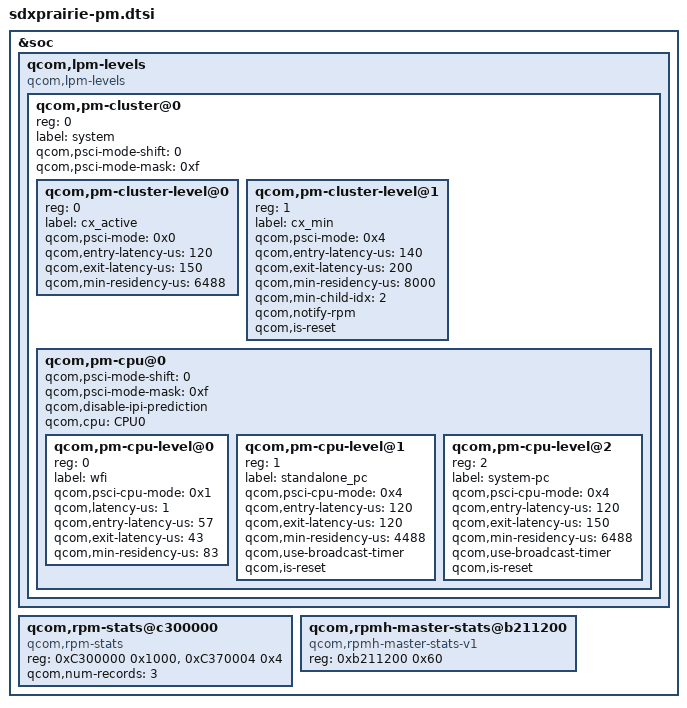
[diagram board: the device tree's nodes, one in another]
/* Copyright (c) 2018, 2020, The Linux Foundation. All rights reserved.
 *
 * This program is free software; you can redistribute it and/or modify
 * it under the terms of the GNU General Public License version 2 and
 * only version 2 as published by the Free Software Foundation.
 *
 * This program is distributed in the hope that it will be useful,
 * but WITHOUT ANY WARRANTY; without even the implied warranty of
 * MERCHANTABILITY or FITNESS FOR A PARTICULAR PURPOSE.  See the
 * GNU General Public License for more details.
 */
#include <dt-bindings/interrupt-controller/arm-gic.h>

&soc {
	qcom,lpm-levels {
		compatible = "qcom,lpm-levels";
		#address-cells = <1>;
		#size-cells = <0>;

		qcom,pm-cluster@0{
			#address-cells = <1>;
			#size-cells = <0>;
			reg = <0>;
			label = "system";
			qcom,psci-mode-shift = <0>;
			qcom,psci-mode-mask = <0xf>;

			qcom,pm-cluster-level@0 {
				reg = <0>;
				label = "cx_active";
				qcom,psci-mode = <0x0>;
				qcom,entry-latency-us = <120>;
				qcom,exit-latency-us = <150>;
				qcom,min-residency-us = <6488>;
			};

			qcom,pm-cluster-level@1 {
				reg = <1>;
				label = "cx_min";
				qcom,psci-mode = <0x4>;
				qcom,entry-latency-us = <140>;
				qcom,exit-latency-us = <200>;
				qcom,min-residency-us = <8000>;
				qcom,min-child-idx = <2>;
				qcom,notify-rpm;
				qcom,is-reset;
			};

			qcom,pm-cpu@0 {
				#address-cells = <1>;
				#size-cells = <0>;
				qcom,psci-mode-shift = <0>;
				qcom,psci-mode-mask = <0xf>;
				qcom,disable-ipi-prediction;
				qcom,cpu = <&CPU0>;

				qcom,pm-cpu-level@0{
					reg = <0>;
					label = "wfi";
					qcom,psci-cpu-mode = <0x1>;
					qcom,latency-us = <1>;
					qcom,entry-latency-us = <57>;
					qcom,exit-latency-us = <43>;
					qcom,min-residency-us = <83>;
				};

				qcom,pm-cpu-level@1 {
					reg = <1>;
					label ="standalone_pc";
					qcom,psci-cpu-mode = <0x4>;
					qcom,entry-latency-us = <120>;
					qcom,exit-latency-us = <120>;
					qcom,min-residency-us = <4488>;
					qcom,use-broadcast-timer;
					qcom,is-reset;
				};

				qcom,pm-cpu-level@2 {
					reg = <2>;
					label = "system-pc";
					qcom,psci-cpu-mode = <0x4>;
					qcom,entry-latency-us = <120>;
					qcom,exit-latency-us = <150>;
					qcom,min-residency-us = <6488>;
					qcom,use-broadcast-timer;
					qcom,is-reset;
				};
			};
		};
	};

	qcom,rpm-stats@c300000 {
		compatible = "qcom,rpm-stats";
		reg = <0xC300000 0x1000>, <0xC370004 0x4>;
		reg-names = "phys_addr_base", "offset_addr";
		qcom,num-records = <3>;
	};

	qcom,rpmh-master-stats@b211200 {
		compatible = "qcom,rpmh-master-stats-v1";
		reg = <0xb211200 0x60>;
	};
};
